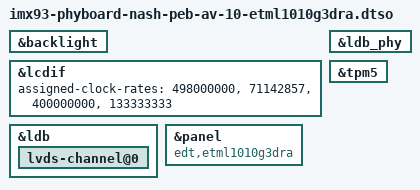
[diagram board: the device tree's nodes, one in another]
// SPDX-License-Identifier: (GPL-2.0+ OR MIT)
/*
 * Copyright (C) 2026 PHYTEC Messtechnik GmbH
 * Author: Florijan Plohl <florijan.plohl@norik.com>
 */

/dts-v1/;
/plugin/;

#include <dt-bindings/clock/imx93-clock.h>
#include <dt-bindings/gpio/gpio.h>
#include "imx93-phyboard-nash-peb-av-10.dtsi"

&backlight {
	status = "okay";
};

&lcdif {
	assigned-clock-rates = <498000000>, <71142857>, <400000000>, <133333333>;
	status = "okay";
};

&ldb {
	status = "okay";

	lvds-channel@0 {
		status = "okay";
	};
};

&ldb_phy {
	status = "okay";
};

&panel {
	compatible = "edt,etml1010g3dra";
	status = "okay";
};

&tpm5 {
	status = "okay";
};
